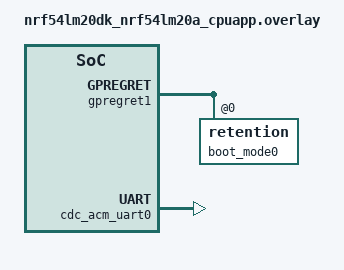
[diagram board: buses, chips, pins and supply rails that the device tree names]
/ {
	chosen {
		zephyr,code-partition = &boot_partition;
		zephyr,boot-mode = &boot_mode0;
		zephyr,uart-mcumgr = &cdc_acm_uart0;
	};

	aliases {
		mcuboot-button0 = &button0;
		mcuboot-led0 = &led0;
	};
};

&gpregret1 {
	status = "okay";

	boot_mode0: boot_mode@0 {
		compatible = "zephyr,retention";
		status = "okay";
		reg = <0x0 0x1>;
	};
};

&zephyr_udc0 {
	cdc_acm_uart0: cdc_acm_uart0 {
		compatible = "zephyr,cdc-acm-uart";
		label = "Daisy MCUboot";
	};
};

#include "../../../boards/shields/daisy/boards/nrf54lm20a_partitions.dtsi"
